# ATSAME51J18A register map
Vendor: Microchip Technology; Series: SAME51; File version: 0
CPU: CM4 r0p1, selectable endian, MPU, FPU, 3 interrupt priority bits
Registers are 32-bit, read-write, reset 0x0 unless marked. A register's access mark holds for its fields unless they carry their own. Offsets are from the block's base; [hi:lo] are bit positions; {n}, {i} and the like mark numbered series; 'fields as' and 'values as' point back to an identical list.

## DAC — Digital-to-Analog Converter
Base 0x43002400; register names take the prefix DAC_
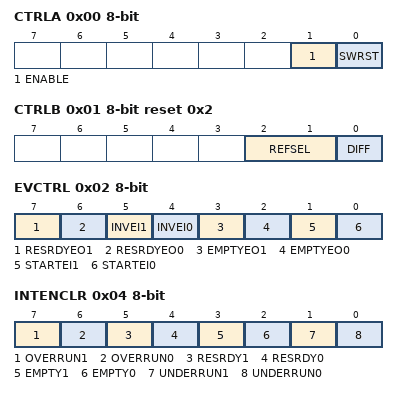
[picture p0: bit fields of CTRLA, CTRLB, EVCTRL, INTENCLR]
0x00 CTRLA 8-bit — Control A
  [1] ENABLE — Enable DAC Controller
  [0] SWRST — Software Reset
0x01 CTRLB 8-bit reset 0x2 — Control B
  [2:1] REFSEL — Reference Selection for DAC0/1
    0=VREFPU (External reference unbuffered); 1=VDDANA (Analog supply); 2=VREFPB (External reference buffered); 3=INTREF (Internal bandgap reference)
  [0] DIFF — Differential mode enable
0x02 EVCTRL 8-bit — Event Control
  [7] RESRDYEO1 — Result Ready Event Output 1
  [6] RESRDYEO0 — Result Ready Event Output 0
  [5] INVEI1 — Enable Invertion of DAC 1 input event
  [4] INVEI0 — Enable Invertion of DAC 0 input event
  [3] EMPTYEO1 — Data Buffer Empty Event Output DAC 1
  [2] EMPTYEO0 — Data Buffer Empty Event Output DAC 0
  [1] STARTEI1 — Start Conversion Event Input DAC 1
  [0] STARTEI0 — Start Conversion Event Input DAC 0
0x04 INTENCLR 8-bit — Interrupt Enable Clear
  [7] OVERRUN1 — Overrun 1 Interrupt Enable
  [6] OVERRUN0 — Overrun 0 Interrupt Enable
  [5] RESRDY1 — Result 1 Ready Interrupt Enable
  [4] RESRDY0 — Result 0 Ready Interrupt Enable
  [3] EMPTY1 — Data Buffer 1 Empty Interrupt Enable
  [2] EMPTY0 — Data Buffer 0 Empty Interrupt Enable
  [1] UNDERRUN1 — Underrun 1 Interrupt Enable
  [0] UNDERRUN0 — Underrun 0 Interrupt Enable
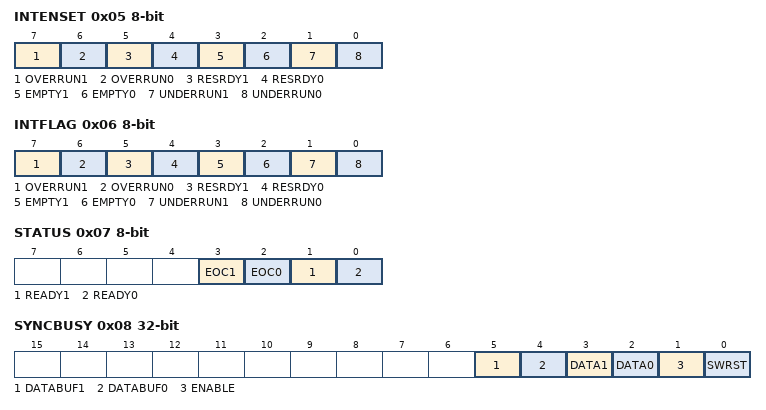
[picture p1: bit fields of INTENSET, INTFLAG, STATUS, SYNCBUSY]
0x05 INTENSET 8-bit — Interrupt Enable Set
  fields as INTENCLR
0x06 INTFLAG 8-bit — Interrupt Flag Status and Clear
  [7] OVERRUN1 write-1-clears — Result 1 Overrun
  [6] OVERRUN0 write-1-clears — Result 0 Overrun
  [5] RESRDY1 write-1-clears — Result 1 Ready
  [4] RESRDY0 write-1-clears — Result 0 Ready
  [3] EMPTY1 write-1-clears — Data Buffer 1 Empty
  [2] EMPTY0 write-1-clears — Data Buffer 0 Empty
  [1] UNDERRUN1 write-1-clears — Result 1 Underrun
  [0] UNDERRUN0 write-1-clears — Result 0 Underrun
0x07 STATUS 8-bit ro
  [3] EOC1 — DAC 1 End of Conversion
  [2] EOC0 — DAC 0 End of Conversion
  [1] READY1 — DAC 1 Startup Ready
  [0] READY0 — DAC 0 Startup Ready
0x08 SYNCBUSY ro — Synchronization Busy
  [5] DATABUF1 — Data Buffer DAC 1
  [4] DATABUF0 — Data Buffer DAC 0
  [3] DATA1 — Data DAC 1
  [2] DATA0 — Data DAC 0
  [1] ENABLE — DAC Enable Status
  [0] SWRST — Software Reset
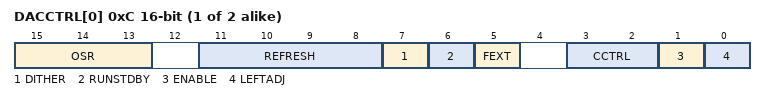
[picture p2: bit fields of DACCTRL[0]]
{0xC+2i} DACCTRL[{i}] (i=0..1) 16-bit — DAC n Control
  [15:13] OSR — Sampling Rate
    0=No Over Sampling; 1=2x Over Sampling Ratio; 2=4x Over Sampling Ratio; 3=8x Over Sampling Ratio; 4=16x Over Sampling Ratio; 5=32x Over Sampling Ratio
  [11:8] REFRESH — Refresh period
    0=Do not Refresh; 1=Refresh every 30 us; 2=Refresh every 60 us; 3=Refresh every 90 us; 4=Refresh every 120 us; 5=Refresh every 150 us; 6=Refresh every 180 us; 7=Refresh every 210 us; 8=Refresh every 240 us; 9=Refresh every 270 us; 10=Refresh every 300 us; 11=Refresh every 330 us; 12=Refresh every 360 us; 13=Refresh every 390 us; 14=Refresh every 420 us; 15=Refresh every 450 us
  [7] DITHER — Dithering Mode
  [6] RUNSTDBY — Run in Standby
  [5] FEXT — Standalone Filter
  [3:2] CCTRL — Current Control
    0=CC100K (100kSPS); 1=CC1M (500kSPS); 2=CC12M (1MSPS)
  [1] ENABLE — Enable DAC0
  [0] LEFTADJ — Left Adjusted Data
{0x10+2i} DATA[{i}] (i=0..1) 16-bit wo — DAC n Data
  [15:0] DATA — DAC0 Data
{0x14+2i} DATABUF[{i}] (i=0..1) 16-bit wo — DAC n Data Buffer
  [15:0] DATABUF — DAC0 Data Buffer
0x18 DBGCTRL 8-bit — Debug Control
  [0] DBGRUN — Debug Run
{0x1C+2i} RESULT[{i}] (i=0..1) 16-bit ro — Filter Result
  [15:0] RESULT

## DSU — Device Service Unit
Base 0x41002000; register names take the prefix DSU_
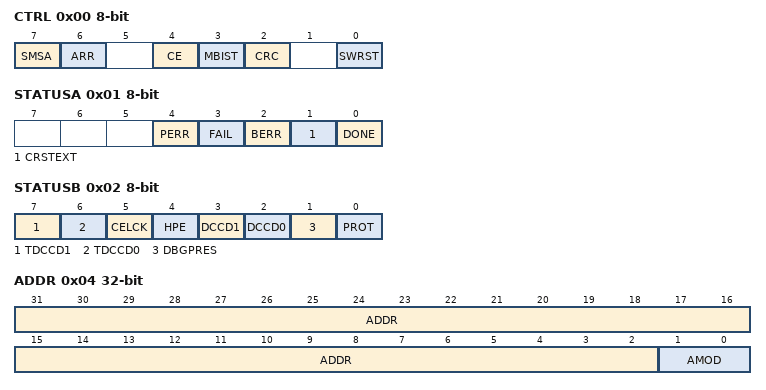
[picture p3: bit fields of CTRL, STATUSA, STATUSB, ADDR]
0x00 CTRL 8-bit wo — Control
  [7] SMSA — Start Memory Stream Access
  [6] ARR — Auxiliary Row Read
  [4] CE — Chip-Erase
  [3] MBIST — Memory built-in self-test
  [2] CRC — 32-bit Cyclic Redundancy Code
  [0] SWRST — Software Reset
0x01 STATUSA 8-bit
  [4] PERR write-1-clears — Protection Error
  [3] FAIL write-1-clears — Failure
  [2] BERR write-1-clears — Bus Error
  [1] CRSTEXT write-1-clears — CPU Reset Phase Extension
  [0] DONE write-1-clears
0x02 STATUSB 8-bit ro
  [7] TDCCD1 — Test Debug Communication Channel 1 Dirty
  [6] TDCCD0 — Test Debug Communication Channel 0 Dirty
  [5] CELCK — Chip Erase Locked
  [4] HPE — Hot-Plugging Enable
  [3] DCCD1 — Debug Communication Channel 1 Dirty
  [2] DCCD0 — Debug Communication Channel 0 Dirty
  [1] DBGPRES — Debugger Present
  [0] PROT — Protected
0x04 ADDR — Address
  [31:2] ADDR — Address
  [1:0] AMOD — Access Mode
0x08 LENGTH
  [31:2] LENGTH
0x0C DATA
{0x10+4i} DCC[{i}] (i=0..1) — Debug Communication Channel n
  [31:0] DATA
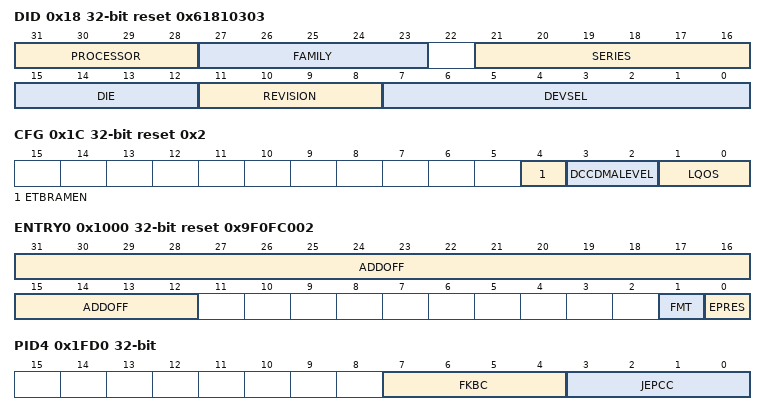
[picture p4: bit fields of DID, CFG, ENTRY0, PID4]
0x18 DID ro reset 0x61810303 — Device Identification
  [31:28] PROCESSOR
    1=CM0P (Cortex-M0+); 2=CM23 (Cortex-M23); 3=CM3 (Cortex-M3); 5=CM4 (Cortex-M4); 6=CM4F (Cortex-M4 with FPU); 7=CM33 (Cortex-M33)
  [27:23] FAMILY
    0=General purpose microcontroller; 1=PicoPower
  [21:16] SERIES
    0=Cortex-M0+ processor, basic feature set; 1=Cortex-M0+ processor, USB
  [15:12] DIE — Die Number
  [11:8] REVISION — Revision Number
  [7:0] DEVSEL — Device Select
0x1C CFG reset 0x2 — Configuration
  [4] ETBRAMEN — Trace Control
  [3:2] DCCDMALEVEL — DMA Trigger Level
    0=EMPTY (Trigger rises when DCC is empty); 1=FULL (Trigger rises when DCC is full)
  [1:0] LQOS — Latency Quality Of Service
{0xF0+4i} DCFG[{i}] (i=0..1) — Device Configuration
  [31:0] DCFG
0x1000 ENTRY0 ro reset 0x9F0FC002 — CoreSight ROM Table Entry 0
  [31:12] ADDOFF — Address Offset
  [1] FMT — Format
  [0] EPRES — Entry Present
0x1004 ENTRY1 ro — CoreSight ROM Table Entry 1
0x1008 END ro — CoreSight ROM Table End
  [31:0] END — End Marker
0x1FCC MEMTYPE ro — CoreSight ROM Table Memory Type
  [0] SMEMP — System Memory Present
0x1FD0 PID4 ro — Peripheral Identification 4
  [7:4] FKBC — 4KB count
  [3:0] JEPCC — JEP-106 Continuation Code
{0x1FC0+4i} PID{i} ro (i=5..7) — Peripheral Identification {i}
0x1FE0 PID0 ro reset 0xD0 — Peripheral Identification 0
  [7:0] PARTNBL — Part Number Low
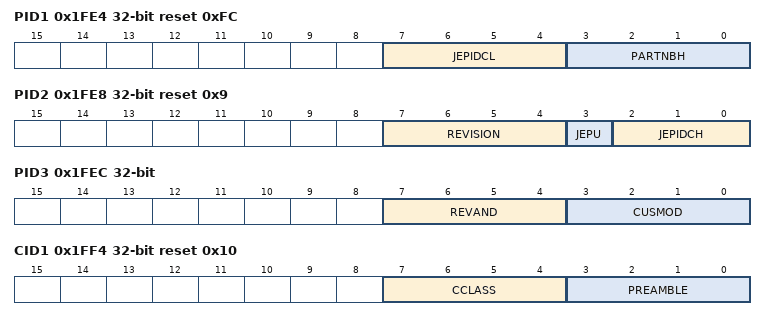
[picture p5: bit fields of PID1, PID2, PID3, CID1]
0x1FE4 PID1 ro reset 0xFC — Peripheral Identification 1
  [7:4] JEPIDCL — Low part of the JEP-106 Identity Code
  [3:0] PARTNBH — Part Number High
0x1FE8 PID2 ro reset 0x9 — Peripheral Identification 2
  [7:4] REVISION — Revision Number
  [3] JEPU — JEP-106 Identity Code is used
  [2:0] JEPIDCH — JEP-106 Identity Code High
0x1FEC PID3 ro — Peripheral Identification 3
  [7:4] REVAND — Revision Number
  [3:0] CUSMOD — ARM CUSMOD
0x1FF0 CID0 ro reset 0xD — Component Identification 0
  [7:0] PREAMBLEB0 — Preamble Byte 0
0x1FF4 CID1 ro reset 0x10 — Component Identification 1
  [7:4] CCLASS — Component Class
  [3:0] PREAMBLE
0x1FF8 CID2 ro reset 0x5 — Component Identification 2
  [7:0] PREAMBLEB2 — Preamble Byte 2
0x1FFC CID3 ro reset 0xB1 — Component Identification 3
  [7:0] PREAMBLEB3 — Preamble Byte 3
